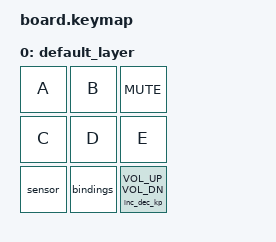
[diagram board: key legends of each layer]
#include <behaviors.dtsi>
#include <dt-bindings/zmk/keys.h>
#include <dt-bindings/zmk/bt.h>

/{
    behaviors {
        inc_dec_kp: inc_dec_kp  {
            compatible = "zmk,behavior-sensor-rotate-var";
            #sensor-binding-cells = <2>;
            bindings = <&kp>, <&kp>;
        };
    };

    keymap {
        compatible = "zmk,keymap";

        default_layer {
            bindings = <
                &kp A    &kp B    &kp C_MUTE
                &kp C    &kp D    &kp E

                sensor-bindings = <&inc_dec_kp C_VOL_UP C_VOL_DN>;
            >;

        };

    };
};


//bindings for dynamic key
bindings = <
    &dynamic_key_0 0 &dynamic_key_0 1 &dynamic_key_0 2
    &dynamic_key_0 3 &dynamic_key_0 4 &dynamic_key_0 5
>;
